AUTOSAR XML (schema 4-0-3)
package /ComponentTypes
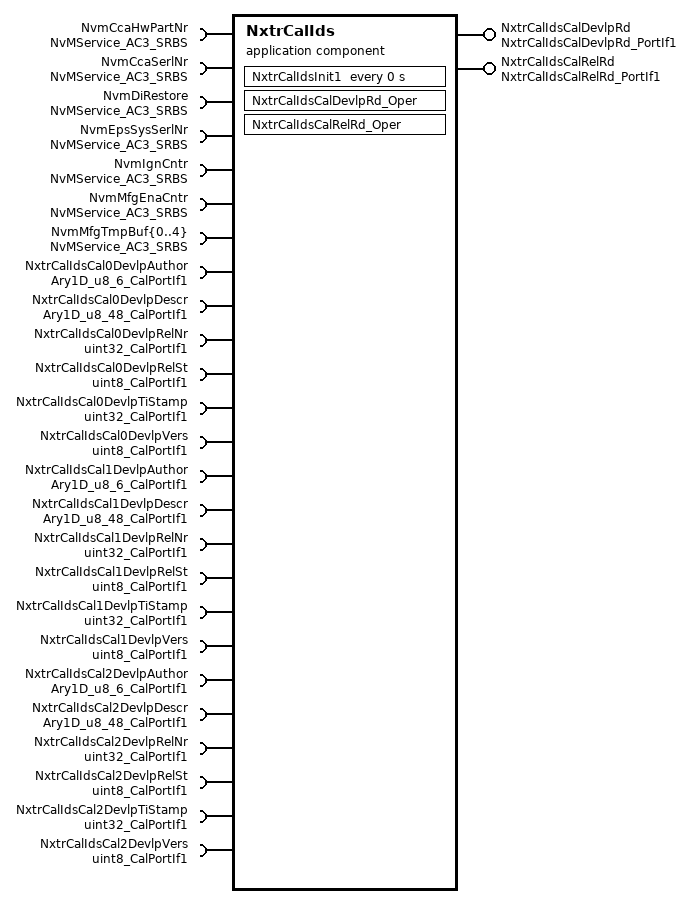
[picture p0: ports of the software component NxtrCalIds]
  application sw component type NxtrCalIds
    provide port NxtrCalIdsCalDevlpRd: server-com-spec{operation=Oper, queue-length=1}, provided-interface=NxtrCalIdsCalDevlpRd_PortIf1
    provide port NxtrCalIdsCalRelRd: server-com-spec{operation=Oper, queue-length=1}, provided-interface=NxtrCalIdsCalRelRd_PortIf1
    29 x require port:
      NvmCcaHwPartNr: required-com-specs=[EraseBlock, GetErrorStatus, InvalidateNvBlock, ReadBlock, SetRamBlockStatus, WriteBlock], required-interface=NvMService_AC3_SRBS
      NvmCcaSerlNr: required-com-specs=[EraseBlock, GetErrorStatus, InvalidateNvBlock, ReadBlock, SetRamBlockStatus, WriteBlock], required-interface=NvMService_AC3_SRBS
      NvmDiRestore: required-com-specs=[EraseBlock, GetErrorStatus, InvalidateNvBlock, ReadBlock, SetRamBlockStatus, WriteBlock], required-interface=NvMService_AC3_SRBS
      NvmEpsSysSerlNr: required-com-specs=[EraseBlock, GetErrorStatus, InvalidateNvBlock, ReadBlock, SetRamBlockStatus, WriteBlock], required-interface=NvMService_AC3_SRBS
      NvmIgnCntr: required-com-specs=[EraseBlock, GetErrorStatus, InvalidateNvBlock, ReadBlock, SetRamBlockStatus, WriteBlock], required-interface=NvMService_AC3_SRBS
      NvmMfgEnaCntr: required-com-specs=[EraseBlock, GetErrorStatus, InvalidateNvBlock, ReadBlock, SetRamBlockStatus, WriteBlock], required-interface=NvMService_AC3_SRBS
      NvmMfgTmpBuf{0..4}: required-com-specs=[EraseBlock, GetErrorStatus, InvalidateNvBlock, ReadBlock, SetRamBlockStatus, WriteBlock], required-interface=NvMService_AC3_SRBS
      NxtrCalIdsCal0DevlpAuthor: parameter-require-com-spec{init-value=6 x 0, parameter=Ary1D}, required-interface=Ary1D_u8_6_CalPortIf1
      NxtrCalIdsCal0DevlpDescr: parameter-require-com-spec{init-value=48 x 0, parameter=Ary1D}, required-interface=Ary1D_u8_48_CalPortIf1
      NxtrCalIdsCal0DevlpRelNr: parameter-require-com-spec{init-value=0, parameter=Val}, required-interface=uint32_CalPortIf1
      NxtrCalIdsCal0DevlpRelSt: parameter-require-com-spec{init-value=0, parameter=Val}, required-interface=uint8_CalPortIf1
      NxtrCalIdsCal0DevlpTiStamp: parameter-require-com-spec{init-value=0, parameter=Val}, required-interface=uint32_CalPortIf1
      NxtrCalIdsCal0DevlpVers: parameter-require-com-spec{init-value=0, parameter=Val}, required-interface=uint8_CalPortIf1
      NxtrCalIdsCal1DevlpAuthor: parameter-require-com-spec{init-value=6 x 0, parameter=Ary1D}, required-interface=Ary1D_u8_6_CalPortIf1
      NxtrCalIdsCal1DevlpDescr: parameter-require-com-spec{init-value=48 x 0, parameter=Ary1D}, required-interface=Ary1D_u8_48_CalPortIf1
      NxtrCalIdsCal1DevlpRelNr: parameter-require-com-spec{init-value=0, parameter=Val}, required-interface=uint32_CalPortIf1
      NxtrCalIdsCal1DevlpRelSt: parameter-require-com-spec{init-value=0, parameter=Val}, required-interface=uint8_CalPortIf1
      NxtrCalIdsCal1DevlpTiStamp: parameter-require-com-spec{init-value=0, parameter=Val}, required-interface=uint32_CalPortIf1
      NxtrCalIdsCal1DevlpVers: parameter-require-com-spec{init-value=0, parameter=Val}, required-interface=uint8_CalPortIf1
      NxtrCalIdsCal2DevlpAuthor: parameter-require-com-spec{init-value=6 x 0, parameter=Ary1D}, required-interface=Ary1D_u8_6_CalPortIf1
      NxtrCalIdsCal2DevlpDescr: parameter-require-com-spec{init-value=48 x 0, parameter=Ary1D}, required-interface=Ary1D_u8_48_CalPortIf1
      NxtrCalIdsCal2DevlpRelNr: parameter-require-com-spec{init-value=0, parameter=Val}, required-interface=uint32_CalPortIf1
      NxtrCalIdsCal2DevlpRelSt: parameter-require-com-spec{init-value=0, parameter=Val}, required-interface=uint8_CalPortIf1
      NxtrCalIdsCal2DevlpTiStamp: parameter-require-com-spec{init-value=0, parameter=Val}, required-interface=uint32_CalPortIf1
      NxtrCalIdsCal2DevlpVers: parameter-require-com-spec{init-value=0, parameter=Val}, required-interface=uint8_CalPortIf1
    behavior NxtrCalIds_InternalBehavior: data-type-mapping=Nexteer
      operation invoked event OIT_NxtrCalIdsCalDevlpRd_Oper_NxtrCalIdsCalDevlpRd_Oper: start-on-event=NxtrCalIdsCalDevlpRd_Oper, operation=NxtrCalIdsCalDevlpRd.Oper
      operation invoked event OIT_NxtrCalIdsCalRelRd_Oper_NxtrCalIdsCalRelRd_Oper: start-on-event=NxtrCalIdsCalRelRd_Oper, operation=NxtrCalIdsCalRelRd.Oper
      timing event CmnMfgSrv_InitEvent: start-on-event=NxtrCalIdsInit1, period=0
      runnable NxtrCalIdsCalDevlpRd_Oper
      runnable NxtrCalIdsCalRelRd_Oper
      runnable NxtrCalIdsInit1
  swc implementation NxtrCalIds_Implementation: behavior=NxtrCalIds_InternalBehavior
    code-descriptors:
      code Default: artifact-descriptors=autosar-engineering-object={short-label=Default, category=SWSRC}
